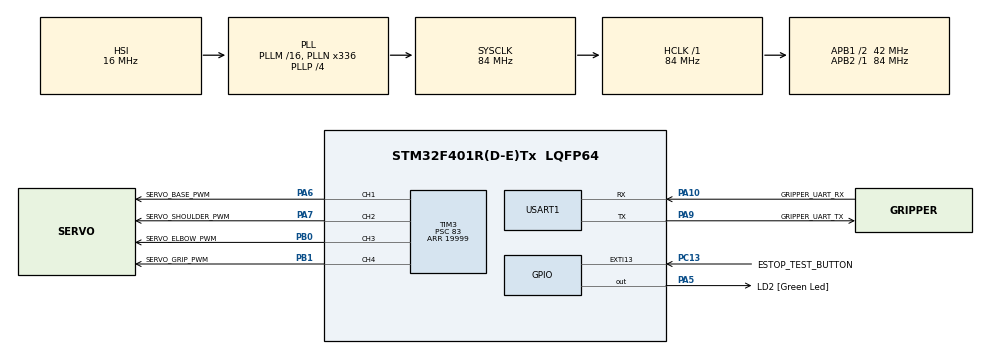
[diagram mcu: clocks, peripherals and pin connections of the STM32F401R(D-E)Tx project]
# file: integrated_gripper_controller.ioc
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Dma.Request0=USART1_RX
Dma.Request1=USART1_TX
Dma.USART1_RX.0.Direction=DMA_PERIPH_TO_MEMORY
Dma.USART1_RX.0.FIFOMode=DMA_FIFOMODE_DISABLE
Dma.USART1_RX.0.Instance=DMA2_Stream5
Dma.USART1_RX.0.MemDataAlignment=DMA_MDATAALIGN_BYTE
Dma.USART1_RX.0.MemInc=DMA_MINC_ENABLE
Dma.USART1_RX.0.Mode=DMA_CIRCULAR
Dma.USART1_RX.0.PeriphDataAlignment=DMA_PDATAALIGN_BYTE
Dma.USART1_RX.0.PeriphInc=DMA_PINC_DISABLE
Dma.USART1_RX.0.Priority=DMA_PRIORITY_HIGH
Dma.USART1_TX.1.Direction=DMA_MEMORY_TO_PERIPH
Dma.USART1_TX.1.FIFOMode=DMA_FIFOMODE_DISABLE
Dma.USART1_TX.1.Instance=DMA2_Stream7
Dma.USART1_TX.1.MemDataAlignment=DMA_MDATAALIGN_BYTE
Dma.USART1_TX.1.MemInc=DMA_MINC_ENABLE
Dma.USART1_TX.1.Mode=DMA_NORMAL
Dma.USART1_TX.1.PeriphDataAlignment=DMA_PDATAALIGN_BYTE
Dma.USART1_TX.1.PeriphInc=DMA_PINC_DISABLE
Dma.USART1_TX.1.Priority=DMA_PRIORITY_MEDIUM
FREERTOS.Tasks01=CommRxTask,32,512,StartCommRxTask,As weak,NULL,Dynamic,NULL,NULL;GripperControlTask,24,768,StartGripperControlTask,As weak,NULL,Dynamic,NULL,NULL;SafetyTask,40,512,StartSafetyTask,As weak,NULL,Dynamic,NULL,NULL;CommTxTask,32,512,StartCommTxTask,As weak,NULL,Dynamic,NULL,NULL;HealthTask,16,512,StartHealthTask,As weak,NULL,Dynamic,NULL,NULL
FREERTOS.configMAX_TASK_NAME_LEN=24
FREERTOS.configTOTAL_HEAP_SIZE=24576
Mcu.Family=STM32F4
Mcu.Name=STM32F401R(D-E)Tx
Mcu.Package=LQFP64
NVIC.DMA2_Stream5_IRQn=true\:5\:0\:false\:false\:true\:true\:false\:true\:true
NVIC.DMA2_Stream7_IRQn=true\:6\:0\:true\:false\:true\:true\:false\:true\:true
NVIC.EXTI15_10_IRQn=true\:5\:0\:false\:false\:true\:true\:true\:true\:true
NVIC.PriorityGroup=NVIC_PRIORITYGROUP_4
NVIC.TIM5_IRQn=true\:0\:0\:false\:false\:true\:false\:false\:true\:true
NVIC.TimeBase=TIM5_IRQn
NVIC.TimeBaseIP=TIM5
NVIC.USART1_IRQn=true\:5\:0\:false\:false\:true\:true\:true\:true\:true
PA10.GPIO_Label=GRIPPER_UART_RX
PA10.Mode=Asynchronous
PA10.Signal=USART1_RX
PA13.GPIO_Label=TMS
PA13.Mode=Trace_Asynchronous_SW
PA13.Signal=SYS_JTMS-SWDIO
PA14.GPIO_Label=TCK
PA14.Mode=Trace_Asynchronous_SW
PA14.Signal=SYS_JTCK-SWCLK
PA5.GPIO_Label=LD2 [Green Led]
PA5.GPIO_Mode=GPIO_MODE_OUTPUT_PP
PA5.GPIO_PuPd=GPIO_NOPULL
PA5.GPIO_Speed=GPIO_SPEED_FREQ_LOW
PA5.Signal=GPIO_Output
PA6.GPIO_Label=SERVO_BASE_PWM
PA6.Signal=S_TIM3_CH1
PA7.GPIO_Label=SERVO_SHOULDER_PWM
PA7.Signal=S_TIM3_CH2
PA9.GPIO_Label=GRIPPER_UART_TX
PA9.Mode=Asynchronous
PA9.Signal=USART1_TX
PB0.GPIO_Label=SERVO_ELBOW_PWM
PB0.Signal=S_TIM3_CH3
PB1.GPIO_Label=SERVO_GRIP_PWM
PB1.Signal=S_TIM3_CH4
PB3.GPIO_Label=SWO
PB3.Mode=Trace_Asynchronous_SW
PB3.Signal=SYS_JTDO-SWO
PC13-ANTI_TAMP.GPIO_Label=ESTOP_TEST_BUTTON
PC13-ANTI_TAMP.GPIO_ModeDefaultEXTI=GPIO_MODE_IT_FALLING
PC13-ANTI_TAMP.GPIO_PuPd=GPIO_NOPULL
PC13-ANTI_TAMP.Signal=GPXTI13
PC14-OSC32_IN.Mode=LSE-External-Oscillator
PC14-OSC32_IN.Signal=RCC_OSC32_IN
PC15-OSC32_OUT.Mode=LSE-External-Oscillator
PC15-OSC32_OUT.Signal=RCC_OSC32_OUT
PH0\ -\ OSC_IN.Mode=HSE-External-Clock-Source
PH0\ -\ OSC_IN.Signal=RCC_OSC_IN
PH1\ -\ OSC_OUT.Mode=HSE-External-Clock-Source
PH1\ -\ OSC_OUT.Signal=RCC_OSC_OUT
ProjectManager.HeapSize=0x200
ProjectManager.StackSize=0x400
ProjectManager.TargetToolchain=STM32CubeIDE
RCC.48MHZClocksFreq_Value=48000000
RCC.AHBFreq_Value=84000000
RCC.APB1CLKDivider=RCC_HCLK_DIV2
RCC.APB1Freq_Value=42000000
RCC.APB1TimFreq_Value=84000000
RCC.APB2Freq_Value=84000000
RCC.APB2TimFreq_Value=84000000
RCC.CortexFreq_Value=84000000
RCC.HCLKFreq_Value=84000000
RCC.HSE_VALUE=8000000
RCC.HSI_VALUE=16000000
RCC.PLLN=336
RCC.PLLP=RCC_PLLP_DIV4
RCC.PLLQ=7
RCC.SYSCLKFreq_VALUE=84000000
RCC.SYSCLKSource=RCC_SYSCLKSOURCE_PLLCLK
RCC.VCOOutputFreq_Value=336000000
SH.S_TIM3_CH1.0=TIM3_CH1,PWM Generation1 CH1
SH.S_TIM3_CH2.0=TIM3_CH2,PWM Generation2 CH2
SH.S_TIM3_CH3.0=TIM3_CH3,PWM Generation3 CH3
SH.S_TIM3_CH4.0=TIM3_CH4,PWM Generation4 CH4
TIM3.AutoReloadPreload=TIM_AUTORELOAD_PRELOAD_ENABLE
TIM3.Channel-PWM\ Generation1\ CH1=TIM_CHANNEL_1
TIM3.Channel-PWM\ Generation2\ CH2=TIM_CHANNEL_2
TIM3.Channel-PWM\ Generation3\ CH3=TIM_CHANNEL_3
TIM3.Channel-PWM\ Generation4\ CH4=TIM_CHANNEL_4
TIM3.Period=19999
TIM3.Prescaler=83
TIM3.Pulse-PWM\ Generation1\ CH1=1500
TIM3.Pulse-PWM\ Generation2\ CH2=1500
TIM3.Pulse-PWM\ Generation3\ CH3=1500
TIM3.Pulse-PWM\ Generation4\ CH4=1500
USART1.VirtualMode=VM_ASYNC
VP_FREERTOS_VS_CMSIS_V2.Mode=CMSIS_V2
VP_SYS_VS_tim5.Mode=TIM5
VP_TIM3_VS_ClockSourceINT.Mode=Internal
board=NUCLEO-F401RE

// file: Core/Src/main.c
/* USER CODE BEGIN Header */
/**
  ******************************************************************************
  * @file           : main.c
  * @brief          : Main program body
  ******************************************************************************
  * @attention
  *
  * Copyright (c) 2026 STMicroelectronics.
  * All rights reserved.
  *
  * This software is licensed under terms that can be found in the LICENSE file
  * in the root directory of this software component.
  * If no LICENSE file comes with this software, it is provided AS-IS.
  *
  ******************************************************************************
  */
/* USER CODE END Header */
#include "main.h"
#include "cmsis_os.h"
#include "dma.h"
#include "tim.h"
#include "usart.h"
#include "gpio.h"

void SystemClock_Config(void);
void MX_FREERTOS_Init(void);

int main(void)
{

  /* MCU Configuration--------------------------------------------------------*/

  /* Reset of all peripherals, Initializes the Flash interface and the Systick. */
  HAL_Init();

  /* Configure the system clock */
  SystemClock_Config();

  /* Initialize all configured peripherals */
  MX_GPIO_Init();
  MX_DMA_Init();
  MX_USART1_UART_Init();
  MX_TIM3_Init();

  /* Init scheduler */
  osKernelInitialize();  /* Call init function for freertos objects (in cmsis_os2.c) */
  MX_FREERTOS_Init();

  /* Start scheduler */
  osKernelStart();

  /* We should never get here as control is now taken by the scheduler */

  /* Infinite loop */
  while (1)
  {

  }
}

void SystemClock_Config(void)
{
  RCC_OscInitTypeDef RCC_OscInitStruct = {0};
  RCC_ClkInitTypeDef RCC_ClkInitStruct = {0};

  /** Configure the main internal regulator output voltage
  */
  __HAL_RCC_PWR_CLK_ENABLE();
  __HAL_PWR_VOLTAGESCALING_CONFIG(PWR_REGULATOR_VOLTAGE_SCALE2);

  /** Initializes the RCC Oscillators according to the specified parameters
  * in the RCC_OscInitTypeDef structure.
  */
  RCC_OscInitStruct.OscillatorType = RCC_OSCILLATORTYPE_HSI;
  RCC_OscInitStruct.HSIState = RCC_HSI_ON;
  RCC_OscInitStruct.HSICalibrationValue = RCC_HSICALIBRATION_DEFAULT;
  RCC_OscInitStruct.PLL.PLLState = RCC_PLL_ON;
  RCC_OscInitStruct.PLL.PLLSource = RCC_PLLSOURCE_HSI;
  RCC_OscInitStruct.PLL.PLLM = 16;
  RCC_OscInitStruct.PLL.PLLN = 336;
  RCC_OscInitStruct.PLL.PLLP = RCC_PLLP_DIV4;
  RCC_OscInitStruct.PLL.PLLQ = 7;
  if (HAL_RCC_OscConfig(&RCC_OscInitStruct) != HAL_OK)
  {
    Error_Handler();
  }

  /** Initializes the CPU, AHB and APB buses clocks
  */
  RCC_ClkInitStruct.ClockType = RCC_CLOCKTYPE_HCLK|RCC_CLOCKTYPE_SYSCLK
                              |RCC_CLOCKTYPE_PCLK1|RCC_CLOCKTYPE_PCLK2;
  RCC_ClkInitStruct.SYSCLKSource = RCC_SYSCLKSOURCE_PLLCLK;
  RCC_ClkInitStruct.AHBCLKDivider = RCC_SYSCLK_DIV1;
  RCC_ClkInitStruct.APB1CLKDivider = RCC_HCLK_DIV2;
  RCC_ClkInitStruct.APB2CLKDivider = RCC_HCLK_DIV1;

  if (HAL_RCC_ClockConfig(&RCC_ClkInitStruct, FLASH_LATENCY_2) != HAL_OK)
  {
    Error_Handler();
  }
}

void HAL_TIM_PeriodElapsedCallback(TIM_HandleTypeDef *htim)
{
  if (htim->Instance == TIM5)
  {
    HAL_IncTick();
  }
}

void Error_Handler(void)
{
  __disable_irq();
  while (1)
  {
  }
}

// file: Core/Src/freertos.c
/* USER CODE BEGIN Header */
/**
  ******************************************************************************
  * File Name          : freertos.c
  * Description        : Code for freertos applications
  ******************************************************************************
  * @attention
  *
  * Copyright (c) 2026 STMicroelectronics.
  * All rights reserved.
  *
  * This software is licensed under terms that can be found in the LICENSE file
  * in the root directory of this software component.
  * If no LICENSE file comes with this software, it is provided AS-IS.
  *
  ******************************************************************************
  */
/* USER CODE END Header */

#include "FreeRTOS.h"
#include "task.h"
#include "main.h"
#include "cmsis_os.h"

/* USER CODE BEGIN Includes */
#include "app_queues.h"

/* USER CODE END Includes */

/* Definitions for CommRxTask */
osThreadId_t CommRxTaskHandle;
const osThreadAttr_t CommRxTask_attributes = {
  .name = "CommRxTask",
  .stack_size = 512 * 4,
  .priority = (osPriority_t) osPriorityAboveNormal,
};
/* Definitions for GripperControlTask */
osThreadId_t GripperControlTaskHandle;
const osThreadAttr_t GripperControlTask_attributes = {
  .name = "GripperControlTask",
  .stack_size = 768 * 4,
  .priority = (osPriority_t) osPriorityNormal,
};
/* Definitions for SafetyTask */
osThreadId_t SafetyTaskHandle;
const osThreadAttr_t SafetyTask_attributes = {
  .name = "SafetyTask",
  .stack_size = 512 * 4,
  .priority = (osPriority_t) osPriorityHigh,
};
/* Definitions for CommTxTask */
osThreadId_t CommTxTaskHandle;
const osThreadAttr_t CommTxTask_attributes = {
  .name = "CommTxTask",
  .stack_size = 512 * 4,
  .priority = (osPriority_t) osPriorityAboveNormal,
};
/* Definitions for HealthTask */
osThreadId_t HealthTaskHandle;
const osThreadAttr_t HealthTask_attributes = {
  .name = "HealthTask",
  .stack_size = 512 * 4,
  .priority = (osPriority_t) osPriorityBelowNormal,
};

void StartCommRxTask(void *argument);
void StartGripperControlTask(void *argument);
void StartSafetyTask(void *argument);
void StartCommTxTask(void *argument);
void StartHealthTask(void *argument);

void MX_FREERTOS_Init(void); /* (MISRA C 2004 rule 8.1) */

void MX_FREERTOS_Init(void) {

  /* USER CODE BEGIN RTOS_QUEUES */
  if (app_queues_init() != osOK)
  {
    Error_Handler();
  }
  /* USER CODE END RTOS_QUEUES */

  /* Create the thread(s) */
  /* creation of CommRxTask */
  CommRxTaskHandle = osThreadNew(StartCommRxTask, NULL, &CommRxTask_attributes);

  /* creation of GripperControlTask */
  GripperControlTaskHandle = osThreadNew(StartGripperControlTask, NULL, &GripperControlTask_attributes);

  /* creation of SafetyTask */
  SafetyTaskHandle = osThreadNew(StartSafetyTask, NULL, &SafetyTask_attributes);

  /* creation of CommTxTask */
  CommTxTaskHandle = osThreadNew(StartCommTxTask, NULL, &CommTxTask_attributes);

  /* creation of HealthTask */
  HealthTaskHandle = osThreadNew(StartHealthTask, NULL, &HealthTask_attributes);

}

__weak void StartCommRxTask(void *argument)
{
  for(;;)
  {
    osDelay(1);
  }
}

__weak void StartGripperControlTask(void *argument)
{
  for(;;)
  {
    osDelay(1);
  }
}

__weak void StartSafetyTask(void *argument)
{
  for(;;)
  {
    osDelay(1);
  }
}

__weak void StartCommTxTask(void *argument)
{
  for(;;)
  {
    osDelay(1);
  }
}

__weak void StartHealthTask(void *argument)
{
  for(;;)
  {
    osDelay(1);
  }
}
